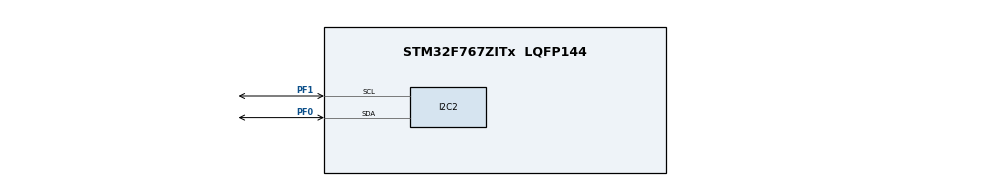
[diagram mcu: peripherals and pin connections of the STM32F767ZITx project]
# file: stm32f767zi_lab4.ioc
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Mcu.Family=STM32F7
Mcu.Name=STM32F767ZITx
Mcu.Package=LQFP144
NVIC.I2C2_ER_IRQn=true\:0\:0\:false\:false\:true\:true\:true\:true
NVIC.I2C2_EV_IRQn=true\:0\:0\:false\:false\:true\:true\:true\:true
NVIC.PriorityGroup=NVIC_PRIORITYGROUP_4
PF0.Mode=I2C
PF0.Signal=I2C2_SDA
PF1.Mode=I2C
PF1.Signal=I2C2_SCL
ProjectManager.HeapSize=0x200
ProjectManager.StackSize=0x400
ProjectManager.TargetToolchain=STM32CubeIDE
RCC.HSE_VALUE=25000000
RCC.HSI_VALUE=16000000
RCC.LSE_VALUE=32768
RCC.USBFreq_Value=96000000
RCC.VCOOutputFreq_Value=192000000
board=custom

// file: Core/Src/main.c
/* USER CODE BEGIN Header */
/**
  ******************************************************************************
  * @file           : main.c
  * @brief          : Main program body
  ******************************************************************************
  * @attention
  *
  * Copyright (c) 2024 STMicroelectronics.
  * All rights reserved.
  *
  * This software is licensed under terms that can be found in the LICENSE file
  * in the root directory of this software component.
  * If no LICENSE file comes with this software, it is provided AS-IS.
  *
  ******************************************************************************
  */
/* USER CODE END Header */
#include "main.h"

/* USER CODE BEGIN Includes */
#include "LCD_lib.c"
/* USER CODE END Includes */

/* USER CODE BEGIN PD */
#define I2C_TIMEOUT    10
#define I2C_ADDRESS_TEMP 0x49
#define TEMP_DATA_ADDRESS 0x00
#define TEMP_CONF_ADDRESS 0x01
/* USER CODE END PD */

I2C_HandleTypeDef hi2c2;

/* USER CODE BEGIN PV */
uint8_t transmitData[10];
uint8_t regData[10];
uint8_t tempDataAddress = TEMP_DATA_ADDRESS;
uint8_t tempConfAddress = TEMP_CONF_ADDRESS;
//char Text_int[16] = {"Temp:    "};
char Text_double[16] = {"Temp:       C   "};
double temperature;
double temperature_old;
/* USER CODE END PV */

void SystemClock_Config(void);
static void MX_GPIO_Init(void);
static void MX_I2C2_Init(void);

int main(void)
{

  /* MCU Configuration--------------------------------------------------------*/

  /* Reset of all peripherals, Initializes the Flash interface and the Systick. */
  HAL_Init();

  /* Configure the system clock */
  SystemClock_Config();

  /* Initialize all configured peripherals */
  MX_GPIO_Init();
  MX_I2C2_Init();
  /* USER CODE BEGIN 2 */
  transmitData[0] = tempConfAddress;
  transmitData[1] = 0x20;// Задание точности датчика 0.125
  HAL_I2C_Master_Transmit(&hi2c2, (I2C_ADDRESS_TEMP << 1), transmitData, 2,  I2C_TIMEOUT);

  LCD_DisplaySet(true, true);
  LCD_DisplayClear(); // clear display, return cursor home
  //LCD_WriteStringAtPos(0, 0, Text_int, 16);
  LCD_WriteStringAtPos(0, 0, Text_double, 16);
  // Вывод пользовательского символа
  uint8_t degree[8] = {2,5,2,0,0,0,0,0};
  LCD_DefineUserChar(degree,0);
  uint8_t strelka_vverh[8] = {
		  0b00100,
		  0b01110,
		  0b10101,
		  0b00100,
		  0b00100,
		  0b00100,
		  0b00100,
		  0b00100};
  uint8_t strelka_vniz[8] = {
		  0b00100,
		  0b00100,
		  0b00100,
		  0b00100,
		  0b00100,
		  0b10101,
		  0b01110,
		  0b00100};
  uint8_t degree_pos = 0;
//  uint8_t strelkavverh_pos = 1;
//  uint8_t strelkavniz_pos = 2;
  LCD_DefineUserChar(strelka_vverh,1);
  LCD_DefineUserChar(strelka_vniz,2);
  LCD_DispUserChar(&degree_pos, 1, 0, 11);
  //LCD_DispUserChar(&strelkavverh_pos, 1, 1, 5);
  HAL_I2C_Master_Transmit(&hi2c2, (I2C_ADDRESS_TEMP << 1), &tempDataAddress, 1,  I2C_TIMEOUT);

  /* USER CODE END 2 */

  /* Infinite loop */
  /* USER CODE BEGIN WHILE */
  while (1)
  {
	  // Через прерывание
	  HAL_I2C_Master_Receive_IT(&hi2c2, (I2C_ADDRESS_TEMP << 1), regData, 2);
	  HAL_Delay(100);
    /* USER CODE END WHILE */

  }
}

void SystemClock_Config(void)
{
  RCC_OscInitTypeDef RCC_OscInitStruct = {0};
  RCC_ClkInitTypeDef RCC_ClkInitStruct = {0};

  /** Configure the main internal regulator output voltage
  */
  __HAL_RCC_PWR_CLK_ENABLE();
  __HAL_PWR_VOLTAGESCALING_CONFIG(PWR_REGULATOR_VOLTAGE_SCALE3);

  /** Initializes the RCC Oscillators according to the specified parameters
  * in the RCC_OscInitTypeDef structure.
  */
  RCC_OscInitStruct.OscillatorType = RCC_OSCILLATORTYPE_HSI;
  RCC_OscInitStruct.HSIState = RCC_HSI_ON;
  RCC_OscInitStruct.HSICalibrationValue = RCC_HSICALIBRATION_DEFAULT;
  RCC_OscInitStruct.PLL.PLLState = RCC_PLL_NONE;
  if (HAL_RCC_OscConfig(&RCC_OscInitStruct) != HAL_OK)
  {
    Error_Handler();
  }

  /** Initializes the CPU, AHB and APB buses clocks
  */
  RCC_ClkInitStruct.ClockType = RCC_CLOCKTYPE_HCLK|RCC_CLOCKTYPE_SYSCLK
                              |RCC_CLOCKTYPE_PCLK1|RCC_CLOCKTYPE_PCLK2;
  RCC_ClkInitStruct.SYSCLKSource = RCC_SYSCLKSOURCE_HSI;
  RCC_ClkInitStruct.AHBCLKDivider = RCC_SYSCLK_DIV1;
  RCC_ClkInitStruct.APB1CLKDivider = RCC_HCLK_DIV1;
  RCC_ClkInitStruct.APB2CLKDivider = RCC_HCLK_DIV1;

  if (HAL_RCC_ClockConfig(&RCC_ClkInitStruct, FLASH_LATENCY_0) != HAL_OK)
  {
    Error_Handler();
  }
}

static void MX_I2C2_Init(void)
{

  hi2c2.Instance = I2C2;
  hi2c2.Init.Timing = 0x00303D5B;
  hi2c2.Init.OwnAddress1 = 0;
  hi2c2.Init.AddressingMode = I2C_ADDRESSINGMODE_7BIT;
  hi2c2.Init.DualAddressMode = I2C_DUALADDRESS_DISABLE;
  hi2c2.Init.OwnAddress2 = 0;
  hi2c2.Init.OwnAddress2Masks = I2C_OA2_NOMASK;
  hi2c2.Init.GeneralCallMode = I2C_GENERALCALL_DISABLE;
  hi2c2.Init.NoStretchMode = I2C_NOSTRETCH_DISABLE;
  if (HAL_I2C_Init(&hi2c2) != HAL_OK)
  {
    Error_Handler();
  }

  /** Configure Analogue filter
  */
  if (HAL_I2CEx_ConfigAnalogFilter(&hi2c2, I2C_ANALOGFILTER_ENABLE) != HAL_OK)
  {
    Error_Handler();
  }

  /** Configure Digital filter
  */
  if (HAL_I2CEx_ConfigDigitalFilter(&hi2c2, 0) != HAL_OK)
  {
    Error_Handler();
  }

}

static void MX_GPIO_Init(void)
{

  /* GPIO Ports Clock Enable */
  __HAL_RCC_GPIOF_CLK_ENABLE();

}

/* USER CODE BEGIN 4 */
void HAL_I2C_MasterTxCpltCallback(I2C_HandleTypeDef *hi2c)
{
  // Вызывается по окончанию отправки данных
}
void HAL_I2C_MasterRxCpltCallback(I2C_HandleTypeDef *hi2c)
{
	// Вызывается по окончанию чтения данных
	static uint8_t strelkavverh_pos = 1;
	static uint8_t strelkavniz_pos = 2;
	if (temperature_old != temperature)
	{
		temperature_old = temperature;

	}
	temperature = (int8_t)(regData[0]) + (regData[1]>>3)*0.0625;
	//LCD_disp_int(0,13,(int)temperature,2);
	//LCD_WriteStringAtPos(idxRow, idxCol, temp_char, 8);
	LCD_disp_double(0,4,temperature);
	if (temperature_old > temperature)
	{
		LCD_DispUserChar(&strelkavniz_pos, 1, 0, 13);
	}
	else if (temperature_old < temperature)
	{
		LCD_DispUserChar(&strelkavverh_pos, 1, 0, 13);

	}
}
/* USER CODE END 4 */

void Error_Handler(void)
{
  __disable_irq();
  while (1)
  {
  }
}
